# MKL28T7_CORE1 register map
Vendor: Freescale Semiconductor, Inc.; Series: Kinetis_L; File version: 1.6
CPU: CM0PLUS r0p0, little endian, no MPU, no FPU, VTOR, 2 interrupt priority bits
Registers are 32-bit, read-write, reset 0x0 unless marked. A register's access mark holds for its fields unless they carry their own. Offsets are from the block's base; [hi:lo] are bit positions; {n}, {i} and the like mark numbered series.

## SMC — System Mode Controller
Base 0x4007E000; register names take the prefix SMC_
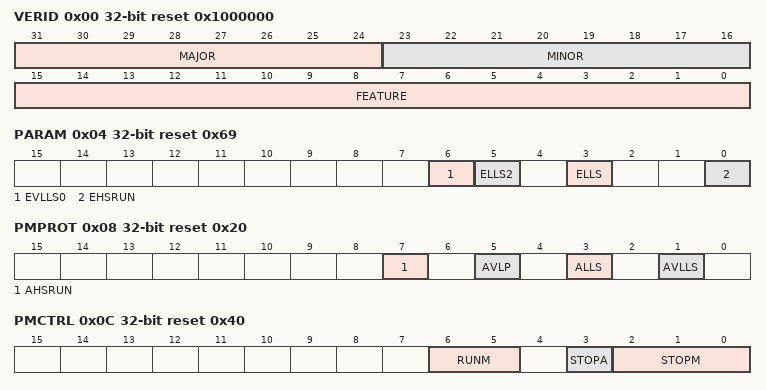
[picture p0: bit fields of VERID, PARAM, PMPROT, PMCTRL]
0x00 VERID ro reset 0x1000000 — SMC Version ID Register
  [31:24] MAJOR — Major Version Number
  [23:16] MINOR — Minor Version Number
  [15:0] FEATURE — Feature Specification Number
    0=Standard features implemented
0x04 PARAM ro reset 0x69 — SMC Parameter Register
  [6] EVLLS0 — Enable VLLS0 (if this mode exists on the SOC)
  [5] ELLS2 — Enable LLS2 (if this mode exists on the SOC)
  [3] ELLS — Enable LLS (if this mode exists on the SOC)
  [0] EHSRUN — Enable HSRUN
0x08 PMPROT reset 0x20 — Power Mode Protection register
  [7] AHSRUN — Allow High Speed Run mode
    0=HSRUN is not allowed; 1=HSRUN is allowed
  [5] AVLP — Allow Very-Low-Power Modes
    0=VLPR, VLPW, and VLPS are not allowed; 1=VLPR, VLPW, and VLPS are allowed
  [3] ALLS — Allow Low-Leakage Stop Mode
    0=Any LLSx mode is not allowed; 1=Any LLSx mode is allowed
  [1] AVLLS — Allow Very-Low-Leakage Stop Mode
    0=Any VLLSx mode is not allowed; 1=Any VLLSx mode is allowed
0x0C PMCTRL reset 0x40 — Power Mode Control register
  [6:5] RUNM — Run Mode Control
    0=Normal Run mode (RUN); 2=Very-Low-Power Run mode (VLPR); 3=High Speed Run mode (HSRUN)
  [3] STOPA ro — Stop Aborted
    0=The previous stop mode entry was successsful; 1=The previous stop mode entry was aborted
  [2:0] STOPM — Stop Mode Control
    0=Normal Stop (STOP); 2=Very-Low-Power Stop (VLPS); 3=Low-Leakage Stop (LLSx); 4=Very-Low-Leakage Stop (VLLSx); 6=Reseved
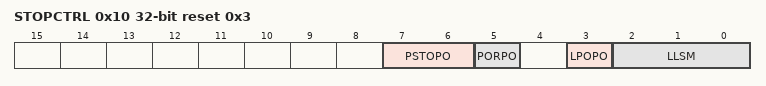
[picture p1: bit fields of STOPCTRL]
0x10 STOPCTRL reset 0x3 — Stop Control Register
  [7:6] PSTOPO — Partial Stop Option
    0=STOP - Normal Stop mode; 1=PSTOP1 - Partial Stop with both system and bus clocks disabled; 2=PSTOP2 - Partial Stop with system clock disabled and bus clock enabled
  [5] PORPO — POR Power Option
    0=POR detect circuit is enabled in VLLS0; 1=POR detect circuit is disabled in VLLS0
  [3] LPOPO — LPO Power Option
    0=LPO clock is enabled in LLS/VLLSx; 1=LPO clock is disabled in LLS/VLLSx
  [2:0] LLSM — LLS or VLLS Mode Control
    0=VLLS0 if PMCTRL[STOPM]=VLLSx, reserved if PMCTRL[STOPM]=LLSx; 1=VLLS1 if PMCTRL[STOPM]=VLLSx, reserved if PMCTRL[STOPM]=LLSx; 2=VLLS2 if PMCTRL[STOPM]=VLLSx, LLS2 if PMCTRL[STOPM]=LLSx; 3=VLLS3 if PMCTRL[STOPM]=VLLSx, LLS3 if PMCTRL[STOPM]=LLSx
0x14 PMSTAT ro reset 0x4 — Power Mode Status register
  [7:0] PMSTAT — Power Mode Status

## INTMUX1 — Interrupt Multiplexer
Base 0x400A4000; register names take the prefix INTMUX1_
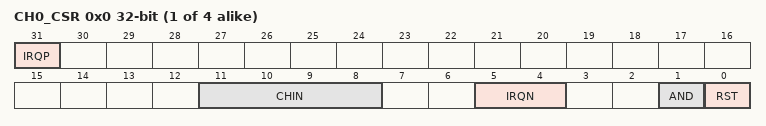
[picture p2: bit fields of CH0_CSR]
{0x0+0x40*i} CH{i}_CSR (i=0..3) — Channel n Control Status Register
  [31] IRQP ro — Channel Interrupt Request Pending
    0=No interrupt is pending; 1=The interrupt output of this channel is pending
  [11:8] CHIN ro — Channel Instance Number
  [5:4] IRQN ro — Channel Input Number
    0=32 interrupt inputs
  [1] AND — Logic AND
    0=Logic OR all enabled interrupt inputs; 1=Logic AND all enabled interrupt inputs
  [0] RST — Software Reset
    0=No operation; 1=Perform a software reset on this channel
{0x4+0x40*i} CH{i}_VEC (i=0..3) ro — Channel n Vector Number Register
  [13:2] VECN — Vector Number
{0x10+0x40*i} CH{i}_IER_31_0 (i=0..3) — Channel n Interrupt Enable Register
  [31:0] INTE — Interrupt Enable
    0=Interrupt is disabled; 1=Interrupt is enabled
{0x20+0x40*i} CH{i}_IPR_31_0 (i=0..3) ro — Channel n Interrupt Pending Register
  [31:0] INTP — Interrupt Pending
    0=No interrupt; 1=Interrupt is pending

## ASMC — ASMC (Auxiliary System Mode Control) Module
Base 0x400F5000; register names take the prefix ASMC_
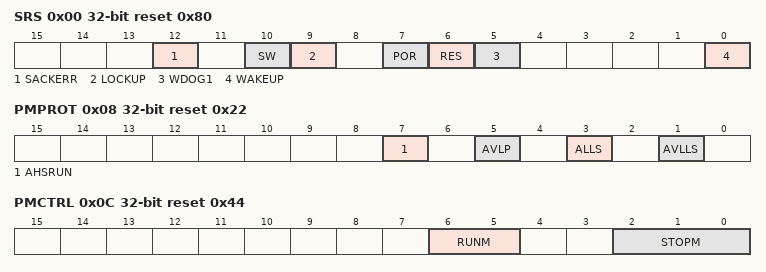
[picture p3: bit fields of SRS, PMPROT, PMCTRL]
0x00 SRS ro reset 0x80 — System Reset Status Register
  [12] SACKERR — Stop Mode Acknowledge Error Reset
    0=Reset not caused by peripheral failure to acknowledge attempt to enter stop mode; 1=Reset caused by peripheral failure to acknowledge attempt to enter stop mode
  [10] SW — Software
    0=Reset not caused by software setting of SYSRESETREQ bit; 1=Reset caused by software setting of SYSRESETREQ bit
  [9] LOCKUP — Core 1 Lockup
    0=Reset not caused by core LOCKUP event; 1=Reset caused by core LOCKUP event
  [7] POR — Power-On Reset
    0=Reset not caused by POR; 1=Reset caused by POR
  [6] RES — Chip Reset not POR
    0=Chip Reset did not occur; 1=Chip Reset caused by a source other than POR occured
  [5] WDOG1 — Watchdog
    0=Reset not caused by watchdog timeout; 1=Reset caused by watchdog timeout
  [0] WAKEUP — Low Leakage Wakeup Reset
    0=Reset not caused by LLWU module wakeup source; 1=Reset caused by LLWU module wakeup source
0x08 PMPROT reset 0x22 — Power Mode Protection register
  [7] AHSRUN — Allow High Speed Run mode
    0=HSRUN is not allowed; 1=HSRUN is allowed
  [5] AVLP — Allow Very-Low-Power Modes
    0=VLPR, VLPW, and VLPS are not allowed; 1=VLPR, VLPW, and VLPS are allowed
  [3] ALLS — Allow Low-Leakage Stop Mode
    0=Any LLSx mode is not allowed; 1=Any LLSx mode is allowed
  [1] AVLLS — Allow Very-Low-Leakage Stop Mode
    0=Any VLLSx mode is not allowed; 1=Any VLLSx mode is allowed
0x0C PMCTRL reset 0x44 — Power Mode Control register
  [6:5] RUNM — Run Mode Control
    0=Normal Run mode (RUN); 2=Very-Low-Power Run mode (VLPR); 3=High Speed Run mode (HSRUN)
  [2:0] STOPM — Stop Mode Control
    0=Normal Stop (STOP); 2=Very-Low-Power Stop (VLPS); 3=Low-Leakage Stop (LLSx); 4=Very-Low-Leakage Stop (VLLSx); 6=Reseved
0x10 STOPCTRL — Stop Control Register
  [7:6] PSTOPO — Partial Stop Option
    0=STOP - Normal Stop mode; 1=PSTOP1 - Partial Stop with both system and bus clocks disabled; 2=PSTOP2 - Partial Stop with system clock disabled and bus clock enabled
0x14 PMSTAT ro reset 0x4 — Power Mode Status register
  [7:0] PMSTAT — Power Mode Status
